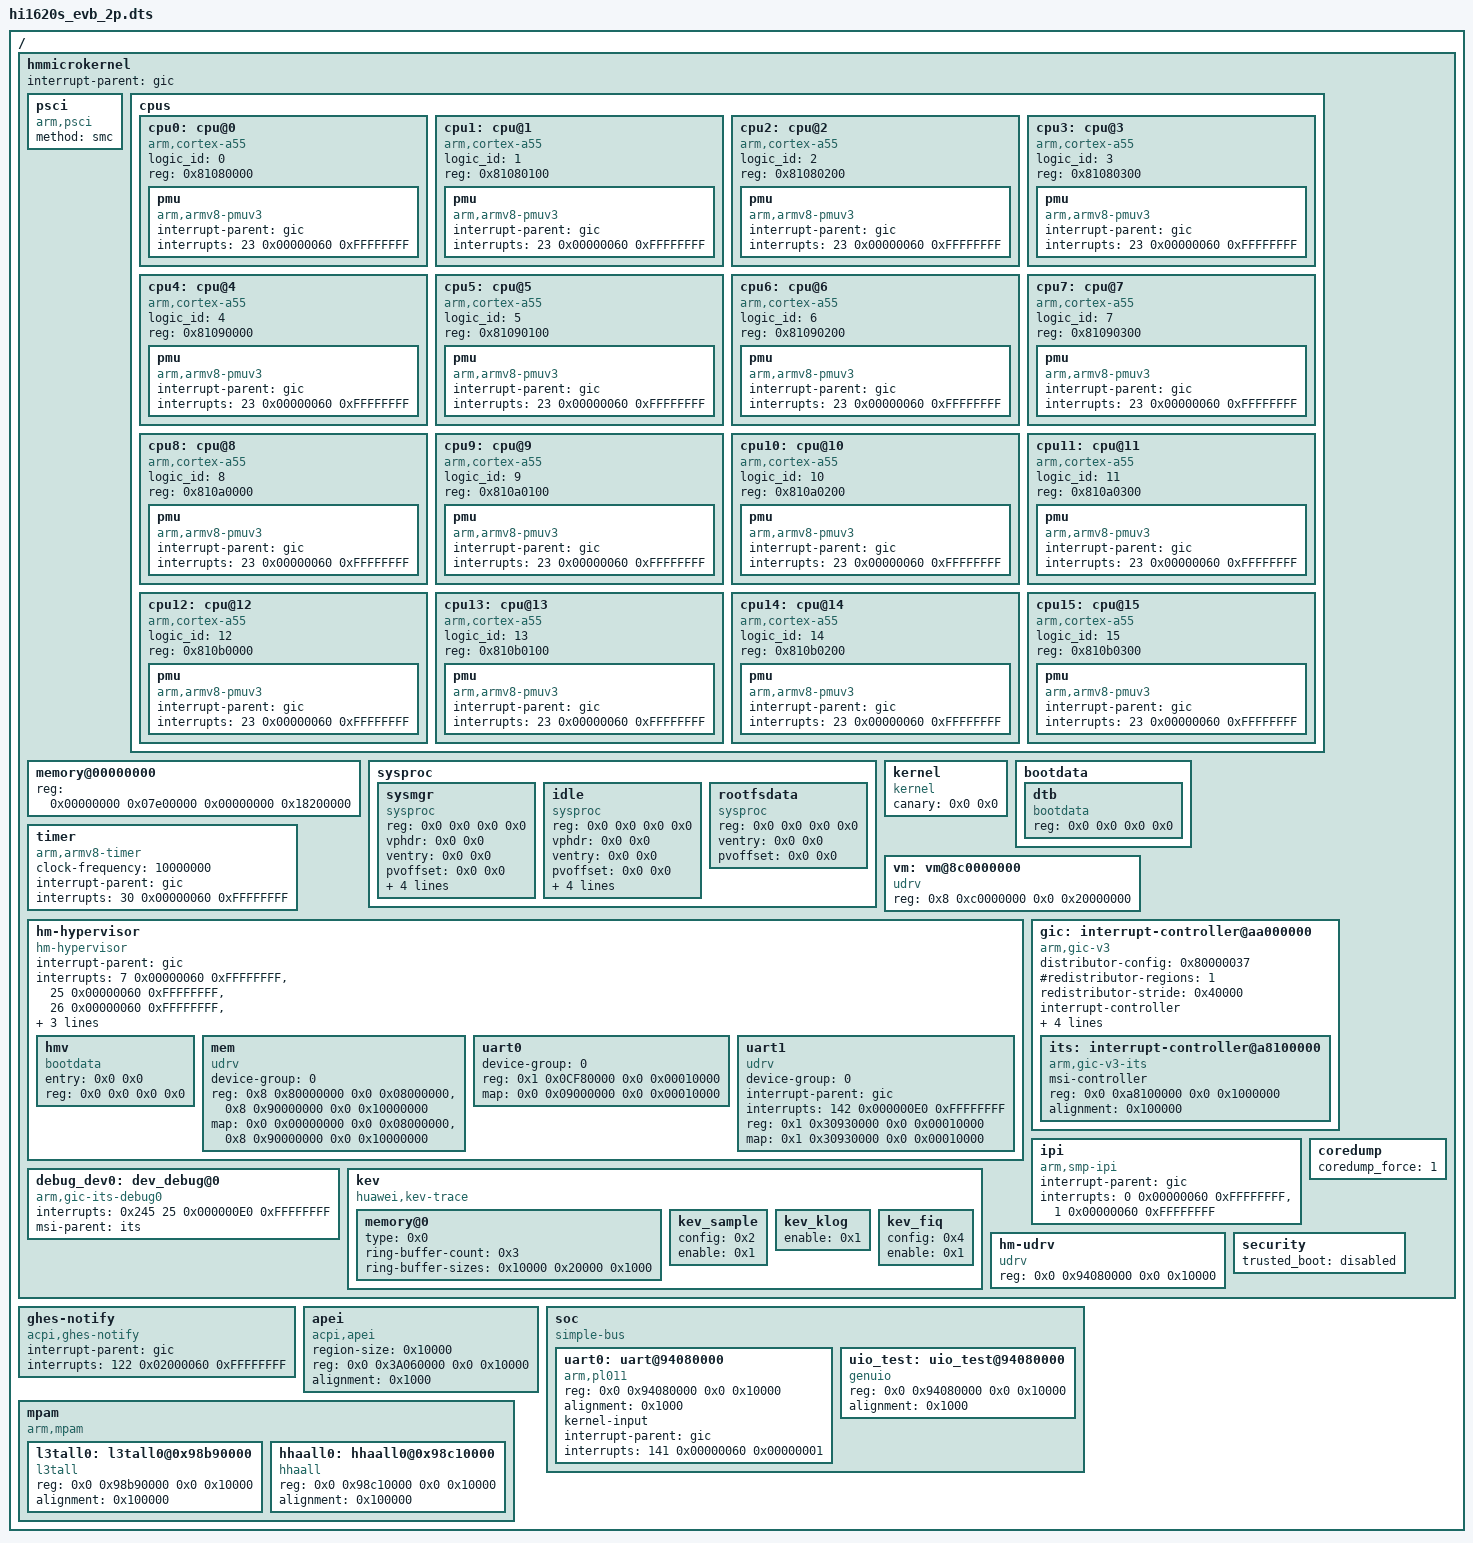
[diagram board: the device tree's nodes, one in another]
/dts-v1/;
/ { #address-cells = <2>; #size-cells = <2>; hmmicrokernel {
	interrupt-parent = <&gic>;
	#address-cells = <2>;
	#size-cells = <2>;

	psci {
		compatible = "arm,psci";
		method = "smc";
	};

	cpus {
		#address-cells = <1>;
		#size-cells = <0>;
		cpu0:  cpu@0  {
			compatible = "arm,cortex-a55", "arm,armv8";
			device_type = "cpu";
			logic_id = <0>;
			reg = <0x81080000>;
			pmu {
				compatible = "arm,armv8-pmuv3";
				interrupt-parent = <&gic>;
				/* PPI 23: PMUIRQ, level triggered, hwprio:0x60 */
				interrupts = <23 0x00000060 0xFFFFFFFF>;
			};
		};
		cpu1:  cpu@1  {
			compatible = "arm,cortex-a55", "arm,armv8";
			device_type = "cpu";
			logic_id = <1>;
			reg = <0x81080100>;
			pmu {
				compatible = "arm,armv8-pmuv3";
				interrupt-parent = <&gic>;
				/* PPI 23: PMUIRQ, level triggered, hwprio:0x60 */
				interrupts = <23 0x00000060 0xFFFFFFFF>;
			};
		};
		cpu2:  cpu@2  {
			compatible = "arm,cortex-a55", "arm,armv8";
			device_type = "cpu";
			logic_id = <2>;
			reg = <0x81080200>;
			pmu {
				compatible = "arm,armv8-pmuv3";
				interrupt-parent = <&gic>;
				/* PPI 23: PMUIRQ, level triggered, hwprio:0x60 */
				interrupts = <23 0x00000060 0xFFFFFFFF>;
			};
		};
		cpu3:  cpu@3  {
			compatible = "arm,cortex-a55", "arm,armv8";
			device_type = "cpu";
			logic_id = <3>;
			reg = <0x81080300>;
			pmu {
				compatible = "arm,armv8-pmuv3";
				interrupt-parent = <&gic>;
				/* PPI 23: PMUIRQ, level triggered, hwprio:0x60 */
				interrupts = <23 0x00000060 0xFFFFFFFF>;
			};
		};
		cpu4:  cpu@4  {
			compatible = "arm,cortex-a55", "arm,armv8";
			device_type = "cpu";
			logic_id = <4>;
			reg = <0x81090000>;
			pmu {
				compatible = "arm,armv8-pmuv3";
				interrupt-parent = <&gic>;
				/* PPI 23: PMUIRQ, level triggered, hwprio:0x60 */
				interrupts = <23 0x00000060 0xFFFFFFFF>;
			};
		};
		cpu5:  cpu@5  {
			compatible = "arm,cortex-a55", "arm,armv8";
			device_type = "cpu";
			logic_id = <5>;
			reg = <0x81090100>;
			pmu {
				compatible = "arm,armv8-pmuv3";
				interrupt-parent = <&gic>;
				/* PPI 23: PMUIRQ, level triggered, hwprio:0x60 */
				interrupts = <23 0x00000060 0xFFFFFFFF>;
			};
		};
		cpu6:  cpu@6  {
			compatible = "arm,cortex-a55", "arm,armv8";
			device_type = "cpu";
			logic_id = <6>;
			reg = <0x81090200>;
			pmu {
				compatible = "arm,armv8-pmuv3";
				interrupt-parent = <&gic>;
				/* PPI 23: PMUIRQ, level triggered, hwprio:0x60 */
				interrupts = <23 0x00000060 0xFFFFFFFF>;
			};
		};
		cpu7:  cpu@7  {
			compatible = "arm,cortex-a55", "arm,armv8";
			device_type = "cpu";
			logic_id = <7>;
			reg = <0x81090300>;
			pmu {
				compatible = "arm,armv8-pmuv3";
				interrupt-parent = <&gic>;
				/* PPI 23: PMUIRQ, level triggered, hwprio:0x60 */
				interrupts = <23 0x00000060 0xFFFFFFFF>;
			};
		};
		cpu8:  cpu@8  {
			compatible = "arm,cortex-a55", "arm,armv8";
			device_type = "cpu";
			logic_id = <8>;
			reg = <0x810a0000>;
			pmu {
				compatible = "arm,armv8-pmuv3";
				interrupt-parent = <&gic>;
				/* PPI 23: PMUIRQ, level triggered, hwprio:0x60 */
				interrupts = <23 0x00000060 0xFFFFFFFF>;
			};
		};
		cpu9:  cpu@9  {
			compatible = "arm,cortex-a55", "arm,armv8";
			device_type = "cpu";
			logic_id = <9>;
			reg = <0x810a0100>;
			pmu {
				compatible = "arm,armv8-pmuv3";
				interrupt-parent = <&gic>;
				/* PPI 23: PMUIRQ, level triggered, hwprio:0x60 */
				interrupts = <23 0x00000060 0xFFFFFFFF>;
			};
		};
		cpu10: cpu@10 {
			compatible = "arm,cortex-a55", "arm,armv8";
			device_type = "cpu";
			logic_id = <10>;
			reg = <0x810a0200>;
			pmu {
				compatible = "arm,armv8-pmuv3";
				interrupt-parent = <&gic>;
				/* PPI 23: PMUIRQ, level triggered, hwprio:0x60 */
				interrupts = <23 0x00000060 0xFFFFFFFF>;
			};
		};
		cpu11: cpu@11 {
			compatible = "arm,cortex-a55", "arm,armv8";
			device_type = "cpu";
			logic_id = <11>;
			reg = <0x810a0300>;
			pmu {
				compatible = "arm,armv8-pmuv3";
				interrupt-parent = <&gic>;
				/* PPI 23: PMUIRQ, level triggered, hwprio:0x60 */
				interrupts = <23 0x00000060 0xFFFFFFFF>;
			};
		};
		cpu12: cpu@12 {
			compatible = "arm,cortex-a55", "arm,armv8";
			device_type = "cpu";
			logic_id = <12>;
			reg = <0x810b0000>;
			pmu {
				compatible = "arm,armv8-pmuv3";
				interrupt-parent = <&gic>;
				/* PPI 23: PMUIRQ, level triggered, hwprio:0x60 */
				interrupts = <23 0x00000060 0xFFFFFFFF>;
			};
		};
		cpu13: cpu@13 {
			compatible = "arm,cortex-a55", "arm,armv8";
			device_type = "cpu";
			logic_id = <13>;
			reg = <0x810b0100>;
			pmu {
				compatible = "arm,armv8-pmuv3";
				interrupt-parent = <&gic>;
				/* PPI 23: PMUIRQ, level triggered, hwprio:0x60 */
				interrupts = <23 0x00000060 0xFFFFFFFF>;
			};
		};
		cpu14: cpu@14 {
			compatible = "arm,cortex-a55", "arm,armv8";
			device_type = "cpu";
			logic_id = <14>;
			reg = <0x810b0200>;
			pmu {
				compatible = "arm,armv8-pmuv3";
				interrupt-parent = <&gic>;
				/* PPI 23: PMUIRQ, level triggered, hwprio:0x60 */
				interrupts = <23 0x00000060 0xFFFFFFFF>;
			};
		};
		cpu15: cpu@15 {
			compatible = "arm,cortex-a55", "arm,armv8";
			device_type = "cpu";
			logic_id = <15>;
			reg = <0x810b0300>;
			pmu {
				compatible = "arm,armv8-pmuv3";
				interrupt-parent = <&gic>;
				/* PPI 23: PMUIRQ, level triggered, hwprio:0x60 */
				interrupts = <23 0x00000060 0xFFFFFFFF>;
			};
		};
//		cpu16: cpu@16 { compatible = "arm,cortex-a55", "arm,armv8"; device_type = "cpu"; logic_id = <16>; reg = <0x811c0000>; pmu { compatible = "arm,armv8-pmuv3"; }; };
//		cpu17: cpu@17 { compatible = "arm,cortex-a55", "arm,armv8"; device_type = "cpu"; logic_id = <17>; reg = <0x811c0100>; pmu { compatible = "arm,armv8-pmuv3"; }; };
//		cpu18: cpu@18 { compatible = "arm,cortex-a55", "arm,armv8"; device_type = "cpu"; logic_id = <18>; reg = <0x811c0200>; pmu { compatible = "arm,armv8-pmuv3"; }; };
//		cpu19: cpu@19 { compatible = "arm,cortex-a55", "arm,armv8"; device_type = "cpu"; logic_id = <19>; reg = <0x811c0300>; pmu { compatible = "arm,armv8-pmuv3"; }; };
//		cpu20: cpu@20 { compatible = "arm,cortex-a55", "arm,armv8"; device_type = "cpu"; logic_id = <20>; reg = <0x811d0000>; pmu { compatible = "arm,armv8-pmuv3"; }; };
//		cpu21: cpu@21 { compatible = "arm,cortex-a55", "arm,armv8"; device_type = "cpu"; logic_id = <21>; reg = <0x811d0100>; pmu { compatible = "arm,armv8-pmuv3"; }; };
//		cpu22: cpu@22 { compatible = "arm,cortex-a55", "arm,armv8"; device_type = "cpu"; logic_id = <22>; reg = <0x811d0200>; pmu { compatible = "arm,armv8-pmuv3"; }; };
//		cpu23: cpu@23 { compatible = "arm,cortex-a55", "arm,armv8"; device_type = "cpu"; logic_id = <23>; reg = <0x811d0300>; pmu { compatible = "arm,armv8-pmuv3"; }; };
	};

	memory@00000000 {
		device_type = "memory";
		reg = <0x00000000 0x07e00000 0x00000000 0x18200000>;
	};

	sysproc {
		#address-cells = <2>;
		#size-cells = <2>;
		sysmgr {
			compatible = "sysproc", "sysmgr";
			/* filled by bootloader */
			reg      = <0x0 0x0 0x0 0x0>;
			vphdr    = <0x0 0x0>;
			ventry   = <0x0 0x0>;
			pvoffset = <0x0 0x0>;
			nphdrs   = <0>;
			stack_start = <0x0 0x0>;
			stack_end = <0x0 0x0>;
			canary = <0x0 0x0>;
		};
		idle {
			compatible = "sysproc", "idle";
			/* filled by bootloader */
			reg      = <0x0 0x0 0x0 0x0>;
			vphdr    = <0x0 0x0>;
			ventry   = <0x0 0x0>;
			pvoffset = <0x0 0x0>;
			nphdrs   = <0>;
			stack_start = <0x0 0x0>;
			stack_end = <0x0 0x0>;
			canary = <0x0 0x0>;
		};
		rootfsdata {
			compatible = "sysproc", "rootfs";
			/* filled by bootloader */
			reg      = <0x0 0x0 0x0 0x0>;
			ventry   = <0x0 0x0>;
			pvoffset = <0x0 0x0>;
		};
	};

	kernel {
		compatible = "kernel";
		/* filled by bootloader */
		canary = <0x0 0x0>;
	};

	bootdata {
		#address-cells = <2>;
		#size-cells = <2>;
		dtb {
			compatible = "bootdata", "dtb";
			/* filled by bootloader */
			reg = <0x0 0x0 0x0 0x0>;
		};
	};

	timer {
		compatible = "arm,armv8-timer";
		clock-frequency = <10000000>;

		/* interrupt settings */
		interrupt-parent = <&gic>;

		/* PPI 30: Non-secure physical timer
		 * level triggered, hwprio:0x60 */
		interrupts = <30 0x00000060 0xFFFFFFFF>;
	};

	/* workaround until we can load files for a VM */
	vm: vm@8c0000000 {
		compatible = "udrv";
		reg = <0x8 0xc0000000 0x0 0x20000000>;
	};

	hm-hypervisor {
		compatible = "hm-hypervisor";
		#address-cells = <2>;
		#size-cells = <2>;

		interrupt-parent = <&gic>;
		interrupts = < 7 0x00000060 0xFFFFFFFF>,
			     <25 0x00000060 0xFFFFFFFF>,
			     <26 0x00000060 0xFFFFFFFF>,
			     <27 0x00000060 0xFFFFFFFF>;

		virtual-timer-irq = <27>;
		vgic-base-address = <0x7F 0xFF000000>;

		hmv {
			compatible = "bootdata";
			/* filled by bootloader */
			entry = <0x0 0x0>;
			reg = <0x0 0x0 0x0 0x0>;
		};

		mem {
			device-group = <0>;
			compatible = "udrv";
			reg = <0x8 0x80000000 0x0 0x08000000>,
			      <0x8 0x90000000 0x0 0x10000000>;
			map = <0x0 0x00000000 0x0 0x08000000>,
			      <0x8 0x90000000 0x0 0x10000000>;
		};

		uart0 {
			device-group = <0>;
			reg = <0x1 0x0CF80000 0x0 0x00010000>;
			map = <0x0 0x09000000 0x0 0x00010000>;
		};

		uart1 {
			device-group = <0>;
			compatible = "udrv";
			interrupt-parent = <&gic>;
			interrupts = <142 0x000000E0 0xFFFFFFFF>;
			reg = <0x1 0x30930000 0x0 0x00010000>;
			map = <0x1 0x30930000 0x0 0x00010000>;
		};
	};

	/* See Documentation/dts-gic.md for interrupts and distributor_config */
	gic: interrupt-controller@aa000000 {
		compatible = "arm,gic-v3";

		#address-cells = <2>;
		#size-cells = <2>;

		/* Enable group 0, Group1NS, Group1S, ARE_NS, ARE_S,
		 * Split EOI and Deactive Mode */
		distributor-config = <0x80000037>;

		#interrupt-cells = <3>;
		#redistributor-regions = <1>;
		redistributor-stride = <0x40000>;
		interrupt-controller;

		reg =	<0x0 0xaa000000 0x0 0x10000>,	/* GICD */
			<0x0 0xae100000 0 0x800000>;	/* GICR */
		alignment = <0x100000 0x100000>;

		interrupts = <25 0x000000E0 0xFFFFFFFF>;

		/* We haven't support this */
		its: interrupt-controller@a8100000 {
			compatible = "arm,gic-v3-its";
			msi-controller;
			reg = <0x0 0xa8100000 0x0 0x1000000>;
			alignment = <0x100000>;
			#interrupt-cells = <4>;
		};
	};

	ipi {
		/* smp ipi */
		compatible = "arm,smp-ipi";

		interrupt-parent = <&gic>;

		/* interrupt settings:
		 * 1st cell: real hardware irq number
		 *     ARM recommendation: ID 0-7 for Non-Secure;
		 *                         ID 8-15 for Secure Interrupt
		 * 2nd cell: interrupt config
		 *     bit [27:26]: Group setting
		 *     bit [24]: Trigger Type
		 *     bit [23:8]: Reserved
		 *     bit [7:0]: Priority
		 * 3rd cell: interrupt target config
		 *     Warning: Send to all cpus by default
		 */
		interrupts =	<0 0x00000060 0xFFFFFFFF>, /* IPI_RESCHEDULE */
				<1 0x00000060 0xFFFFFFFF>; /* IPI_CALL_FUNC */
	};

	/* used to debug its driver */
	debug_dev0:dev_debug@0 {
		compatible = "arm,gic-its-debug0";
		/* devid is 0x245, nr is 25, config is 0x00000002 0xFFFFFFFF */
		interrupts = <0x245 25 0x000000E0 0xFFFFFFFF>;
		msi-parent = <&its>;
	};

	kev {
		compatible = "huawei,kev-trace";

		memory@0 {
			type = <0x0>;
			ring-buffer-count = <0x3>;
			ring-buffer-sizes = <0x10000 0x20000 0x1000>;
		};
		kev_sample {
			config = <0x2>;
			enable = <0x1>;
		};
		kev_klog {
			enable = <0x1>;
		};
		kev_fiq {
			config = <0x4>;
			enable = <0x1>;
		};
	};

	hm-udrv {
		compatible = "udrv";
		reg = <0x0 0x94080000 0x0 0x10000>;
	};

	coredump {
		coredump_force = <1>;
	};
	security {
		trusted_boot = "disabled";
	};
	};

        ghes-notify {
                compatible = "acpi,ghes-notify";

                interrupt-parent = <&gic>;
                 /* interrupt settings:
                 * 1st cell: real hardware irq number
                 *     ARM recommendation: ID 0-7 for Non-Secure;
                 *                         ID 8-15 for Secure Interrupt
                 * 2nd cell: interrupt config
                 *     bit [27:26]: Group setting
                 *     bit [25]: Trigger Type
                 *     bit [7:0]: Priority
                 * 3rd cell: interrupt target config
                 *     Warning: Send to all cpus by default
                 */
                interrupts = <122 0x02000060 0xFFFFFFFF>;
        };

        apei {
                compatible = "acpi,apei";
                #address-cells = <2>;
                #size-cells = <2>;
                region-size = <0x10000>;
                reg = <0x0 0x3A060000 0x0 0x10000>;
                alignment = <0x1000>;
        };

	soc {
		compatible = "simple-bus";
		#address-cells = <2>;
		#size-cells = <2>;
		ranges;

		uart0: uart@94080000 {
			compatible = "arm,pl011", "arm,pl011,uart";
			reg = <0x0 0x94080000 0x0 0x10000>;
			alignment = <0x1000>;

			/* kernel control input */
			kernel-input;

			interrupt-parent=<&gic>;
			interrupts=<141 0x00000060 0x00000001>;
		};

		uio_test: uio_test@94080000 {
			compatible = "genuio";
			reg = <0x0 0x94080000 0x0 0x10000>;
			alignment = <0x1000>;
		};

	};

	mpam {
		compatible = "arm,mpam";
		#address-cells = <2>;
		#size-cells = <2>;

		/* L3T: L3 cache. it includes L3 Tag and L3 Data */
		l3tall0: l3tall0@0x98b90000 {
			compatible = "l3tall";
			reg = <0x0 0x98b90000 0x0 0x10000>;
			alignment = <0x100000>;
		};
		/* HHA: hydra home agent. HHA is located between L3T and DDR,
		 * providing the system with a DDR access channel. When the
		 * CPU accesses memory, it reads DDR data through the
		 * corresponding HHA.
		 */
		hhaall0: hhaall0@0x98c10000 {
			compatible = "hhaall";
			reg = <0x0 0x98c10000 0x0 0x10000>;
			alignment = <0x100000>;
		};
	};
};
